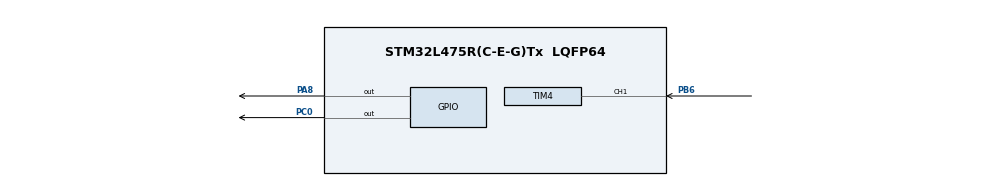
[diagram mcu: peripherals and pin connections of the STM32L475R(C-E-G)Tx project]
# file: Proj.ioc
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Mcu.Family=STM32L4
Mcu.Name=STM32L475R(C-E-G)Tx
Mcu.Package=LQFP64
NVIC.PriorityGroup=NVIC_PRIORITYGROUP_4
NVIC.TIM4_IRQn=true\:0\:0\:false\:false\:true\:true\:true
NVIC.TIM6_DAC_IRQn=true\:0\:0\:false\:false\:true\:true\:true
PA8.Signal=GPIO_Output
PB6.Signal=S_TIM4_CH1
PC0.Signal=GPIO_Output
ProjectManager.HeapSize=0x200
ProjectManager.StackSize=0x400
ProjectManager.TargetToolchain=TrueSTUDIO
RCC.HSE_VALUE=8000000
RCC.HSI_VALUE=16000000
RCC.LSE_VALUE=32768
RCC.MSI_VALUE=4000000
RCC.VCOOutputFreq_Value=32000000
SH.S_TIM4_CH1.0=TIM4_CH1,Input_Capture1_from_TI1
TIM4.Channel-Input_Capture1_from_TI1=TIM_CHANNEL_1
TIM4.Period=42000
TIM4.Prescaler=1
TIM4.TIM_MasterOutputTrigger=TIM_TRGO_UPDATE
TIM6.Period=2000
TIM6.Prescaler=100
TIM6.TIM_MasterOutputTrigger=TIM_TRGO_UPDATE
VP_TIM4_VS_ClockSourceINT.Mode=Internal
VP_TIM6_VS_ClockSourceINT.Mode=Enable_Timer
board=custom

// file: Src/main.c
/* USER CODE BEGIN Header */
/**
  ******************************************************************************
  * @file           : main.c
  * @brief          : Main program body
  ******************************************************************************
  * @attention
  *
  * <h2><center>&copy; Copyright (c) 2020 STMicroelectronics.
  * All rights reserved.</center></h2>
  *
  * This software component is licensed by ST under BSD 3-Clause license,
  * the "License"; You may not use this file except in compliance with the
  * License. You may obtain a copy of the License at:
  *                        opensource.org/licenses/BSD-3-Clause
  *
  ******************************************************************************
  */
/* USER CODE END Header */

#include "main.h"

TIM_HandleTypeDef htim4;
TIM_HandleTypeDef htim6;

void SystemClock_Config(void);
static void MX_GPIO_Init(void);
static void MX_TIM4_Init(void);
static void MX_TIM6_Init(void);

/* USER CODE BEGIN 0 */
#define LED1_Pin GPIO_PIN_8
#define LED1_GPIO_Port GPIOA
#define LED2_Pin GPIO_PIN_15
#define LED2_GPIO_Port GPIOA
/* USER CODE END 0 */

int main(void)
{

  /* MCU Configuration--------------------------------------------------------*/

  /* Reset of all peripherals, Initializes the Flash interface and the Systick. */
  HAL_Init();

  /* Configure the system clock */
  SystemClock_Config();

  /* Initialize all configured peripherals */
  MX_GPIO_Init();
  MX_TIM4_Init();
  MX_TIM6_Init();
  /* USER CODE BEGIN 2 */
  HAL_TIM_Base_Start(&htim4);
  HAL_TIM_Base_Start_IT(&htim4);
  HAL_TIM_Base_Start(&htim6);
  HAL_TIM_Base_Start_IT(&htim6);
  /* USER CODE END 2 */

  /* Infinite loop */
  /* USER CODE BEGIN WHILE */
  while (1)
  {
//	  HAL_GPIO_TogglePin(LED1_GPIO_Port, LED1_Pin);//*
//	  HAL_GPIO_TogglePin(LED2_GPIO_Port, LED2_Pin);
	  HAL_Delay(1000);
    /* USER CODE END WHILE */

  }
}

void SystemClock_Config(void)
{
  RCC_OscInitTypeDef RCC_OscInitStruct = {0};
  RCC_ClkInitTypeDef RCC_ClkInitStruct = {0};

  /** Initializes the CPU, AHB and APB busses clocks
  */
  RCC_OscInitStruct.OscillatorType = RCC_OSCILLATORTYPE_MSI;
  RCC_OscInitStruct.MSIState = RCC_MSI_ON;
  RCC_OscInitStruct.MSICalibrationValue = 0;
  RCC_OscInitStruct.MSIClockRange = RCC_MSIRANGE_6;
  RCC_OscInitStruct.PLL.PLLState = RCC_PLL_NONE;
  if (HAL_RCC_OscConfig(&RCC_OscInitStruct) != HAL_OK)
  {
    Error_Handler();
  }
  /** Initializes the CPU, AHB and APB busses clocks
  */
  RCC_ClkInitStruct.ClockType = RCC_CLOCKTYPE_HCLK|RCC_CLOCKTYPE_SYSCLK
                              |RCC_CLOCKTYPE_PCLK1|RCC_CLOCKTYPE_PCLK2;
  RCC_ClkInitStruct.SYSCLKSource = RCC_SYSCLKSOURCE_MSI;
  RCC_ClkInitStruct.AHBCLKDivider = RCC_SYSCLK_DIV1;
  RCC_ClkInitStruct.APB1CLKDivider = RCC_HCLK_DIV1;
  RCC_ClkInitStruct.APB2CLKDivider = RCC_HCLK_DIV1;

  if (HAL_RCC_ClockConfig(&RCC_ClkInitStruct, FLASH_LATENCY_0) != HAL_OK)
  {
    Error_Handler();
  }
  /** Configure the main internal regulator output voltage
  */
  if (HAL_PWREx_ControlVoltageScaling(PWR_REGULATOR_VOLTAGE_SCALE1) != HAL_OK)
  {
    Error_Handler();
  }
}

static void MX_TIM4_Init(void)
{

  TIM_ClockConfigTypeDef sClockSourceConfig = {0};
  TIM_MasterConfigTypeDef sMasterConfig = {0};
  TIM_IC_InitTypeDef sConfigIC = {0};

  htim4.Instance = TIM4;
  htim4.Init.Prescaler = 1;
  htim4.Init.CounterMode = TIM_COUNTERMODE_UP;
  htim4.Init.Period = 42000;
  htim4.Init.ClockDivision = TIM_CLOCKDIVISION_DIV1;
  htim4.Init.AutoReloadPreload = TIM_AUTORELOAD_PRELOAD_DISABLE;
  if (HAL_TIM_Base_Init(&htim4) != HAL_OK)
  {
    Error_Handler();
  }
  sClockSourceConfig.ClockSource = TIM_CLOCKSOURCE_INTERNAL;
  if (HAL_TIM_ConfigClockSource(&htim4, &sClockSourceConfig) != HAL_OK)
  {
    Error_Handler();
  }
  if (HAL_TIM_IC_Init(&htim4) != HAL_OK)
  {
    Error_Handler();
  }
  sMasterConfig.MasterOutputTrigger = TIM_TRGO_UPDATE;
  sMasterConfig.MasterSlaveMode = TIM_MASTERSLAVEMODE_DISABLE;
  if (HAL_TIMEx_MasterConfigSynchronization(&htim4, &sMasterConfig) != HAL_OK)
  {
    Error_Handler();
  }
  sConfigIC.ICPolarity = TIM_INPUTCHANNELPOLARITY_RISING;
  sConfigIC.ICSelection = TIM_ICSELECTION_DIRECTTI;
  sConfigIC.ICPrescaler = TIM_ICPSC_DIV1;
  sConfigIC.ICFilter = 0;
  if (HAL_TIM_IC_ConfigChannel(&htim4, &sConfigIC, TIM_CHANNEL_1) != HAL_OK)
  {
    Error_Handler();
  }

}

static void MX_TIM6_Init(void)
{

  TIM_MasterConfigTypeDef sMasterConfig = {0};

  htim6.Instance = TIM6;
  htim6.Init.Prescaler = 100;
  htim6.Init.CounterMode = TIM_COUNTERMODE_UP;
  htim6.Init.Period = 2000;
  htim6.Init.AutoReloadPreload = TIM_AUTORELOAD_PRELOAD_DISABLE;
  if (HAL_TIM_Base_Init(&htim6) != HAL_OK)
  {
    Error_Handler();
  }
  sMasterConfig.MasterOutputTrigger = TIM_TRGO_UPDATE;
  sMasterConfig.MasterSlaveMode = TIM_MASTERSLAVEMODE_DISABLE;
  if (HAL_TIMEx_MasterConfigSynchronization(&htim6, &sMasterConfig) != HAL_OK)
  {
    Error_Handler();
  }

}

static void MX_GPIO_Init(void)
{
  GPIO_InitTypeDef GPIO_InitStruct = {0};

  /* GPIO Ports Clock Enable */
  __HAL_RCC_GPIOC_CLK_ENABLE();
  __HAL_RCC_GPIOA_CLK_ENABLE();
  __HAL_RCC_GPIOB_CLK_ENABLE();

  /*Configure GPIO pin Output Level */
  HAL_GPIO_WritePin(GPIOC, GPIO_PIN_0, GPIO_PIN_RESET);

  /*Configure GPIO pin Output Level */
  HAL_GPIO_WritePin(GPIOA, GPIO_PIN_8, GPIO_PIN_RESET);

  /*Configure GPIO pin : PC0 */
  GPIO_InitStruct.Pin = GPIO_PIN_0;
  GPIO_InitStruct.Mode = GPIO_MODE_OUTPUT_PP;
  GPIO_InitStruct.Pull = GPIO_NOPULL;
  GPIO_InitStruct.Speed = GPIO_SPEED_FREQ_LOW;
  HAL_GPIO_Init(GPIOC, &GPIO_InitStruct);

  /*Configure GPIO pin : PA8 */
  GPIO_InitStruct.Pin = GPIO_PIN_8;
  GPIO_InitStruct.Mode = GPIO_MODE_OUTPUT_PP;
  GPIO_InitStruct.Pull = GPIO_NOPULL;
  GPIO_InitStruct.Speed = GPIO_SPEED_FREQ_LOW;
  HAL_GPIO_Init(GPIOA, &GPIO_InitStruct);

}

/* USER CODE BEGIN 4 */
void HAL_TIM_PeriodElapsedCallback(TIM_HandleTypeDef *htim)
{
	HAL_GPIO_WritePin(LED1_GPIO_Port, LED1_Pin, GPIO_PIN_SET);
//	HAL_GPIO_WritePin(LED2_GPIO_Port, LED2_Pin, GPIO_PIN_SET);
//	asm("nop");
	HAL_GPIO_WritePin(LED1_GPIO_Port, LED1_Pin, GPIO_PIN_RESET);
//	HAL_GPIO_WritePin(LED2_GPIO_Port, LED2_Pin, GPIO_PIN_RESET);

}
/* USER CODE END 4 */

void Error_Handler(void)
{
}

/************************ (C) COPYRIGHT STMicroelectronics *****END OF FILE****/
